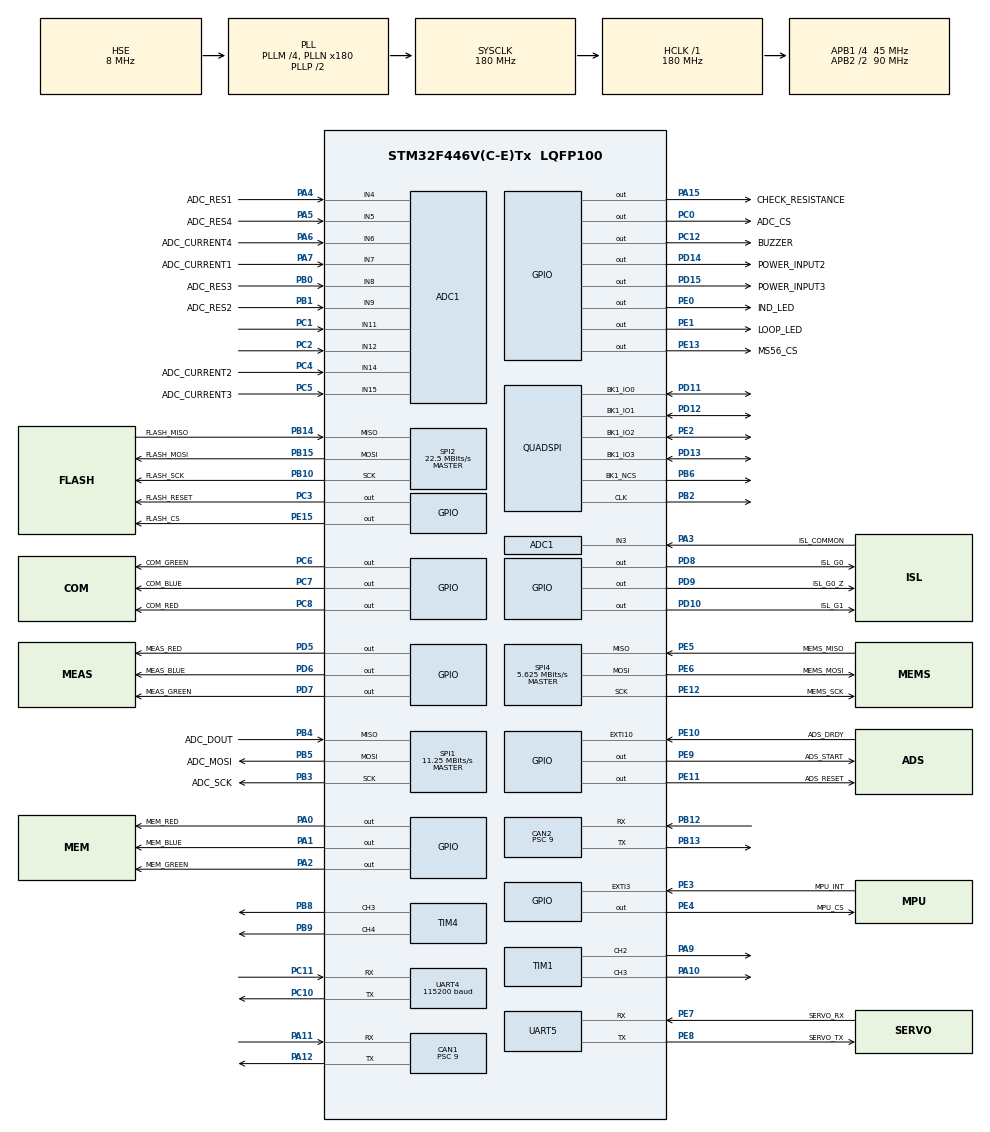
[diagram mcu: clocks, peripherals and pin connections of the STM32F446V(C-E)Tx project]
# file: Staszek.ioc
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NVIC.CAN1_RX1_IRQn=true\:5\:0\:true\:false\:true\:true\:true
PH0-OSC_IN.Signal=RCC_OSC_IN
SPI4.VirtualType=VM_MASTER
QUADSPI.ClockPrescaler=3
SPI1.VirtualType=VM_MASTER
SPI2.VirtualType=VM_MASTER
PB10.Mode=Full_Duplex_Master
Dma.SPI4_TX.1.PeriphDataAlignment=DMA_PDATAALIGN_BYTE
PC12.Signal=GPIO_Output
PB14.GPIO_Label=FLASH_MISO
PC6.GPIO_Label=COM_GREEN
PA6.GPIO_Label=ADC_CURRENT4
PB13.Signal=CAN2_TX
PD6.GPIO_Label=MEAS_BLUE
PE6.GPIO_Label=MEMS_MOSI
RCC.SYSCLKSource=RCC_SYSCLKSOURCE_PLLCLK
VP_TIM1_VS_no_output1.Mode=PWM Generation1 No Output
PA9.GPIO_ModeDefaultPP=GPIO_MODE_AF_OD
NVIC.SPI4_IRQn=true\:5\:0\:true\:false\:true\:true\:true
NVIC.CAN1_TX_IRQn=true\:5\:0\:true\:false\:true\:true\:true
Dma.SPI2_RX.2.Direction=DMA_PERIPH_TO_MEMORY
SPI1.Direction=SPI_DIRECTION_2LINES
Dma.SPI1_RX.5.Instance=DMA2_Stream0
PE2.Mode=Single Bank 1
RCC.APB2TimFreq_Value=180000000
PB6.Signal=QUADSPI_BK1_NCS
PC7.Signal=GPIO_Output
PB6.Mode=Single Bank 1
SPI1.CalculateBaudRate=11.25 MBits/s
PC3.Signal=GPIO_Output
PD8.Signal=GPIO_Output
PE5.Signal=SPI4_MISO
PA10.GPIO_ModeDefaultPP=GPIO_MODE_AF_OD
PE1.Signal=GPIO_Output
Dma.SPI4_RX.0.Priority=DMA_PRIORITY_LOW
QUADSPI.FlashSize=31
NVIC.EXTI15_10_IRQn=true\:5\:0\:true\:false\:true\:true\:true
Dma.SPI2_RX.2.MemDataAlignment=DMA_MDATAALIGN_BYTE
TIM4.Channel-PWM\ Generation3\ CH3=TIM_CHANNEL_3
NVIC.TIM8_TRG_COM_TIM14_IRQn=true\:0\:0\:true\:false\:true\:false\:true
PB2.Signal=QUADSPI_CLK
PB3.Mode=Full_Duplex_Master
SH.ADCx_IN15.0=ADC1_IN15,IN15
Dma.SPI2_RX.2.PeriphInc=DMA_PINC_DISABLE
PC4.GPIO_Label=ADC_CURRENT2
PE9.Signal=GPIO_Output
PB14.Mode=Full_Duplex_Master
PB1.GPIO_Label=ADC_RES2
PE4.GPIO_Label=MPU_CS
SH.ADCx_IN8.0=ADC1_IN8,IN8
SPI2.CalculateBaudRate=22.5 MBits/s
PE2.Signal=QUADSPI_BK1_IO2
Dma.SPI2_RX.2.PeriphDataAlignment=DMA_PDATAALIGN_BYTE
Dma.SPI1_RX.5.Priority=DMA_PRIORITY_LOW
Dma.SPI1_RX.5.FIFOMode=DMA_FIFOMODE_DISABLE
PE10.Signal=GPXTI10
Dma.SPI4_RX.0.Mode=DMA_NORMAL
VP_TIM1_VS_ClockSourceINT.Mode=Internal
ADC1.SamplingTime-0\#ChannelRegularConversion=ADC_SAMPLETIME_3CYCLES
CAN1.Prescaler=9
Mcu.Package=LQFP100
PB9.Signal=S_TIM4_CH4
PB1.Signal=ADCx_IN9
NVIC.TimeBase=TIM8_UP_TIM13_IRQn
SPI2.Mode=SPI_MODE_MASTER
SH.ADCx_IN14.0=ADC1_IN14,IN14
PD12.Signal=QUADSPI_BK1_IO1
Dma.SPI2_RX.2.MemInc=DMA_MINC_ENABLE
NVIC.TimeBaseIP=TIM13
PA10.Signal=S_TIM1_CH3
PE12.GPIO_Label=MEMS_SCK
PC11.Mode=Asynchronous
SH.ADCx_IN9.0=ADC1_IN9,IN9
RCC.APB2CLKDivider=RCC_HCLK_DIV2
RCC.APB1TimFreq_Value=90000000
PB13.Mode=Slave
VP_TIM14_VS_ClockSourceINT.Mode=Enable_Timer
TIM4.Channel-PWM\ Generation4\ CH4=TIM_CHANNEL_4
PE10.GPIO_Label=ADS_DRDY
PA4.GPIO_Label=ADC_RES1
PD15.Signal=GPIO_Output
CAN1.CalculateTimeQuantum=200.0
NVIC.UART4_IRQn=true\:5\:0\:true\:false\:true\:true\:true
PE12.Mode=Full_Duplex_Master
Dma.SPI2_TX.3.MemInc=DMA_MINC_ENABLE
NVIC.QUADSPI_IRQn=true\:5\:0\:true\:false\:true\:true\:true
NVIC.CAN2_TX_IRQn=true\:5\:0\:true\:false\:true\:true\:true
ADC1.Rank-0\#ChannelRegularConversion=1
PD9.GPIO_Label=ISL_G0_Z
SH.ADCx_IN6.0=ADC1_IN6,IN6
Dma.QUADSPI.6.Instance=DMA2_Stream7
Dma.SPI1_RX.5.MemDataAlignment=DMA_MDATAALIGN_BYTE
PC6.Signal=GPIO_Output
PC2.Signal=ADCx_IN12
PD7.Signal=GPIO_Output
NVIC.DMA2_Stream1_IRQn=true\:5\:0\:true\:false\:true\:false\:true
UART5.VirtualMode=Asynchronous
PC0.Signal=GPIO_Output
RCC.APB1CLKDivider=RCC_HCLK_DIV4
UART4.VirtualMode=Asynchronous
NVIC.CAN2_RX1_IRQn=true\:5\:0\:true\:false\:true\:true\:true
PA0-WKUP.GPIO_Label=MEM_RED
PA0-WKUP.Signal=GPIO_Output
Dma.SPI4_TX.1.PeriphInc=DMA_PINC_DISABLE
Dma.SPI2_TX.3.PeriphDataAlignment=DMA_PDATAALIGN_BYTE
PE8.Mode=Asynchronous
PD10.Signal=GPIO_Output
Dma.SPI2_RX.2.FIFOMode=DMA_FIFOMODE_DISABLE
SH.ADCx_IN7.0=ADC1_IN7,IN7
Dma.QUADSPI.6.MemDataAlignment=DMA_MDATAALIGN_BYTE
PE8.GPIO_Label=SERVO_TX
Dma.QUADSPI.6.PeriphDataAlignment=DMA_PDATAALIGN_BYTE
PA9.Signal=S_TIM1_CH2
TIM1.Channel-PWM\ Generation2\ CH2=TIM_CHANNEL_2
VP_TIM8_VS_ClockSourceINT.Mode=Internal
Dma.SPI2_TX.3.Mode=DMA_NORMAL
PE9.GPIO_Label=ADS_START
PB10.Signal=SPI2_SCK
PB14.Signal=SPI2_MISO
PA5.Signal=ADCx_IN5
PB9.GPIO_ModeDefaultPP=GPIO_MODE_AF_OD
PE1.GPIO_Label=LOOP_LED
NVIC.SPI1_IRQn=true\:5\:0\:true\:false\:true\:true\:true
Dma.SPI2_TX.3.Instance=DMA1_Stream4
PE6.Mode=Full_Duplex_Master
PE15.Signal=GPIO_Output
PB4.GPIO_Label=ADC_DOUT
PB15.GPIO_Label=FLASH_MOSI
PE8.Signal=UART5_TX
SPI1.Mode=SPI_MODE_MASTER
PA1.GPIO_Label=MEM_BLUE
Dma.QUADSPI.6.Mode=DMA_NORMAL
SH.ADCx_IN4.0=ADC1_IN4,IN4
PA13.Mode=Serial_Wire
TIM8.Period=49
PC7.GPIO_Label=COM_BLUE
Dma.SPI1_TX.4.PeriphInc=DMA_PINC_DISABLE
Dma.SPI1_TX.4.Priority=DMA_PRIORITY_LOW
PA4.Signal=ADCx_IN4
PB5.Signal=SPI1_MOSI
ADC1.master=1
PE13.GPIO_Label=MS56_CS
PD12.Mode=Single Bank 1
PA5.GPIO_Label=ADC_RES4
PD11.Signal=QUADSPI_BK1_IO0
PE5.GPIO_Label=MEMS_MISO
PC12.GPIO_Label=BUZZER
PA11.Signal=CAN1_RX
ProjectManager.HeapSize=0x200
NVIC.CAN2_SCE_IRQn=true\:5\:0\:true\:false\:true\:true\:true
NVIC.TIM8_UP_TIM13_IRQn=true\:0\:0\:true\:false\:true\:true\:true
SH.ADCx_IN5.0=ADC1_IN5,IN5
VP_TIM4_VS_ClockSourceINT.Mode=Internal
Dma.SPI4_TX.1.Priority=DMA_PRIORITY_LOW
NVIC.PriorityGroup=NVIC_PRIORITYGROUP_4
PE3.Signal=GPXTI3
Dma.SPI2_TX.3.PeriphInc=DMA_PINC_DISABLE
PC3.GPIO_Label=FLASH_RESET
Dma.SPI2_TX.3.FIFOMode=DMA_FIFOMODE_DISABLE
TIM1.Channel-PWM\ Generation3\ CH3=TIM_CHANNEL_3
PB0.Signal=ADCx_IN8
Dma.SPI4_RX.0.MemDataAlignment=DMA_MDATAALIGN_BYTE
PC1.Signal=ADCx_IN11
NVIC.CAN1_RX0_IRQn=true\:5\:0\:true\:false\:true\:true\:true
Mcu.Family=STM32F4
Dma.SPI1_TX.4.MemInc=DMA_MINC_ENABLE
RCC.CortexFreq_Value=180000000
NVIC.CAN2_RX0_IRQn=true\:5\:0\:true\:false\:true\:true\:true
Dma.SPI4_TX.1.MemDataAlignment=DMA_MDATAALIGN_BYTE
PE11.GPIO_Label=ADS_RESET
Dma.SPI1_RX.5.PeriphDataAlignment=DMA_PDATAALIGN_BYTE
PC10.Signal=UART4_TX
SPI4.Direction=SPI_DIRECTION_2LINES
NVIC.EXTI3_IRQn=true\:5\:0\:true\:false\:true\:true\:true
PC0.GPIO_Label=ADC_CS
PA11.Mode=Master
PB0.GPIO_Label=ADC_RES3
Dma.QUADSPI.6.PeriphInc=DMA_PINC_DISABLE
NVIC.DMA1_Stream4_IRQn=true\:5\:0\:true\:false\:true\:false\:true
PB15.Signal=SPI2_MOSI
ProjectManager.StackSize=0x400
PD13.Signal=QUADSPI_BK1_IO3
PA15.GPIO_Label=CHECK_RESISTANCE
Dma.SPI4_RX.0.MemInc=DMA_MINC_ENABLE
PA12.Signal=CAN1_TX
SPI4.Mode=SPI_MODE_MASTER
UART4.BaudRate=115200
RCC.HCLKFreq_Value=180000000
SH.ADCx_IN3.0=ADC1_IN3,IN3
Dma.SPI4_TX.1.Direction=DMA_MEMORY_TO_PERIPH
Dma.SPI2_TX.3.Priority=DMA_PRIORITY_LOW
NVIC.DMA2_Stream0_IRQn=true\:5\:0\:true\:false\:true\:false\:true
NVIC.CAN1_SCE_IRQn=true\:5\:0\:true\:false\:true\:true\:true
RCC.AHBFreq_Value=180000000
PH0-OSC_IN.Mode=HSE-External-Oscillator
ADC1.Channel-0\#ChannelRegularConversion=ADC_CHANNEL_3
Dma.SPI2_RX.2.Instance=DMA1_Stream3
RCC.HSE_VALUE=8000000
PB8.GPIO_ModeDefaultPP=GPIO_MODE_AF_OD
Dma.SPI1_TX.4.FIFOMode=DMA_FIFOMODE_DISABLE
PB4.Mode=Full_Duplex_Master
PE13.Signal=GPIO_Output
PA14.Mode=Serial_Wire
CAN2.Prescaler=9
Dma.QUADSPI.6.Direction=DMA_PERIPH_TO_MEMORY
PB5.Mode=Full_Duplex_Master
Dma.SPI4_TX.1.Instance=DMA2_Stream1
NVIC.SPI2_IRQn=true\:5\:0\:true\:false\:true\:true\:true
Dma.SPI1_TX.4.MemDataAlignment=DMA_MDATAALIGN_BYTE
PE4.Signal=GPIO_Output
SPI4.BaudRatePrescaler=SPI_BAUDRATEPRESCALER_16
PD7.GPIO_Label=MEAS_GREEN
PH1-OSC_OUT.Mode=HSE-External-Oscillator
PA6.Signal=ADCx_IN6
PB12.Mode=Slave
NVIC.DMA2_Stream7_IRQn=true\:5\:0\:true\:false\:true\:false\:true
CAN2.BS1=CAN_BS1_6TQ
CAN2.BS2=CAN_BS2_6TQ
Dma.QUADSPI.6.FIFOMode=DMA_FIFOMODE_DISABLE
Dma.SPI2_RX.2.Priority=DMA_PRIORITY_LOW
Dma.QUADSPI.6.Priority=DMA_PRIORITY_LOW
Dma.SPI1_TX.4.Direction=DMA_MEMORY_TO_PERIPH
PD5.GPIO_Label=MEAS_RED
PA2.GPIO_Label=MEM_GREEN
Dma.SPI1_RX.5.PeriphInc=DMA_PINC_DISABLE
PA15.Signal=GPIO_Output
PE0.GPIO_Label=IND_LED
TIM8.Prescaler=179
PB5.GPIO_Label=ADC_MOSI
Dma.Request2=SPI2_RX
Dma.Request1=SPI4_TX
Dma.SPI4_RX.0.PeriphInc=DMA_PINC_DISABLE
Dma.Request4=SPI1_TX
Dma.Request3=SPI2_TX
Dma.Request6=QUADSPI
Dma.Request5=SPI1_RX
SPI2.Direction=SPI_DIRECTION_2LINES
PC5.Signal=ADCx_IN15
PE7.Signal=UART5_RX
PD6.Signal=GPIO_Output
Dma.Request0=SPI4_RX
SPI1.BaudRatePrescaler=SPI_BAUDRATEPRESCALER_8
Dma.SPI2_TX.3.Direction=DMA_MEMORY_TO_PERIPH
PB4.Signal=SPI1_MISO
PA3.Signal=ADCx_IN3
PB3.GPIO_Label=ADC_SCK
Dma.SPI4_TX.1.MemInc=DMA_MINC_ENABLE
RCC.PLLSourceVirtual=RCC_PLLSOURCE_HSE
Dma.SPI4_TX.1.Mode=DMA_NORMAL
PD15.GPIO_Label=POWER_INPUT3
PC9.GPIO_Label=STASZEK_RECO_PWM
Dma.SPI2_TX.3.MemDataAlignment=DMA_MDATAALIGN_BYTE
SH.S_TIM4_CH4.0=TIM4_CH4,PWM Generation4 CH4
PC11.Signal=UART4_RX
Dma.SPI1_TX.4.PeriphDataAlignment=DMA_PDATAALIGN_BYTE
PC8.Signal=GPIO_Output
PC4.Signal=ADCx_IN14
PC10.Mode=Asynchronous
Dma.QUADSPI.6.MemInc=DMA_MINC_ENABLE
PD9.Signal=GPIO_Output
PD5.Signal=GPIO_Output
Dma.SPI1_TX.4.Instance=DMA2_Stream5
Dma.SPI2_RX.2.Mode=DMA_NORMAL
TIM1.Channel-PWM\ Generation1\ No\ Output=TIM_CHANNEL_1
PD8.GPIO_Label=ISL_G0
PC8.GPIO_Label=COM_RED
PA13.Signal=SYS_JTMS-SWDIO
SH.ADCx_IN12.0=ADC1_IN12,IN12
Dma.SPI4_TX.1.FIFOMode=DMA_FIFOMODE_DISABLE
PE15.GPIO_Label=FLASH_CS
CAN1.BS2=CAN_BS2_6TQ
CAN1.BS1=CAN_BS1_6TQ
ProjectManager.TargetToolchain=SW4STM32
PB10.GPIO_Label=FLASH_SCK
SH.S_TIM4_CH3.0=TIM4_CH3,PWM Generation3 CH3
PD13.Mode=Single Bank 1
Dma.SPI4_RX.0.PeriphDataAlignment=DMA_PDATAALIGN_BYTE
RCC.USBFreq_Value=180000000
PD10.GPIO_Label=ISL_G1
NVIC.DMA2_Stream3_IRQn=true\:5\:0\:true\:false\:true\:false\:true
PE11.Signal=GPIO_Output
PA1.Signal=GPIO_Output
SPI4.CRCCalculation=SPI_CRCCALCULATION_DISABLE
board=custom
RCC.VCOOutputFreq_Value=360000000
PB15.Mode=Full_Duplex_Master
RCC.APB2Freq_Value=90000000
SH.ADCx_IN11.0=ADC1_IN11,IN11
VP_SYS_VS_tim13.Mode=TIM13
SH.S_TIM1_CH2.0=TIM1_CH2,PWM Generation2 CH2
PE5.Mode=Full_Duplex_Master
NVIC.DMA2_Stream5_IRQn=true\:5\:0\:true\:false\:true\:false\:true
CAN2.CalculateTimeQuantum=200.0
PH1-OSC_OUT.Signal=RCC_OSC_OUT
SPI4.CalculateBaudRate=5.625 MBits/s
PD14.GPIO_Label=POWER_INPUT2
PE6.Signal=SPI4_MOSI
Mcu.Name=STM32F446V(C-E)Tx
PE0.Signal=GPIO_Output
PE7.GPIO_Label=SERVO_RX
PE12.Signal=SPI4_SCK
PA2.Signal=GPIO_Output
PD14.Signal=GPIO_Output
PB3.Signal=SPI1_SCK
RCC.SYSCLKFreq_VALUE=180000000
PE7.Mode=Asynchronous
PA7.GPIO_Label=ADC_CURRENT1
PA12.Mode=Master
PC5.GPIO_Label=ADC_CURRENT3
Dma.SPI4_RX.0.Direction=DMA_PERIPH_TO_MEMORY
Dma.SPI1_RX.5.MemInc=DMA_MINC_ENABLE
Dma.SPI4_RX.0.Instance=DMA2_Stream3
PB2.Mode=Single Bank 1
PA14.Signal=SYS_JTCK-SWCLK
Dma.SPI1_TX.4.Mode=DMA_NORMAL
PD11.Mode=Single Bank 1
SH.S_TIM1_CH3.0=TIM1_CH3,PWM Generation3 CH3
ADC1.NbrOfConversionFlag=1
RCC.PLLM=4
Dma.SPI1_RX.5.Mode=DMA_NORMAL
RCC.PLLN=180
PB8.Signal=S_TIM4_CH3
PE3.GPIO_Label=MPU_INT
Dma.SPI1_RX.5.Direction=DMA_PERIPH_TO_MEMORY
NVIC.DMA1_Stream3_IRQn=true\:5\:0\:true\:false\:true\:false\:true
PC9.Signal=S_TIM3_CH4
RCC.APB1Freq_Value=45000000
PB12.Signal=CAN2_RX
PA3.GPIO_Label=ISL_COMMON
SH.S_TIM3_CH4.0=TIM3_CH4
PA7.Signal=ADCx_IN7
Dma.SPI4_RX.0.FIFOMode=DMA_FIFOMODE_DISABLE

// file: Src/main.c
/* USER CODE BEGIN Header */
/**
  ******************************************************************************
  * @file           : main.c
  * @brief          : Main program body
  ******************************************************************************
  * @attention
  *
  * <h2><center>&copy; Copyright (c) 2020 STMicroelectronics.
  * All rights reserved.</center></h2>
  *
  * This software component is licensed by ST under BSD 3-Clause license,
  * the "License"; You may not use this file except in compliance with the
  * License. You may obtain a copy of the License at:
  *                        opensource.org/licenses/BSD-3-Clause
  *
  ******************************************************************************
  */
/* USER CODE END Header */

#include "main.h"
#include "adc.h"
#include "can.h"
#include "dma.h"
#include "quadspi.h"
#include "spi.h"
#include "tim.h"
#include "usart.h"
#include "gpio.h"

/* USER CODE BEGIN Includes */
#include "SS_common.h"
#include "SS_platform.h"

/* USER CODE END Includes */

void SystemClock_Config(void);

int main(void)
{

  /* MCU Configuration--------------------------------------------------------*/

  /* Reset of all peripherals, Initializes the Flash interface and the Systick. */
  HAL_Init();

  /* Configure the system clock */
  SystemClock_Config();

  /* Initialize all configured peripherals */
  MX_GPIO_Init();
  MX_DMA_Init();
  MX_UART4_Init();
  MX_UART5_Init();
  MX_SPI1_Init();
  MX_ADC1_Init();
  MX_SPI4_Init();
  MX_SPI2_Init();
  MX_QUADSPI_Init();
  MX_TIM14_Init();
  /* USER CODE BEGIN 2 */

    MX_CAN1_Init();
    MX_CAN2_Init();
    MX_TIM1_Init();
    MX_TIM4_Init();
    MX_TIM8_Init();
    HAL_GPIO_WritePin(MPU_CS_GPIO_Port, MPU_CS_Pin, GPIO_PIN_SET);

    SS_platform_init();

    SS_init();

  /* USER CODE END 2 */

  /* Infinite loop */
    while(1) {

    }
}

void SystemClock_Config(void)
{
  RCC_OscInitTypeDef RCC_OscInitStruct = {0};
  RCC_ClkInitTypeDef RCC_ClkInitStruct = {0};

  /** Configure the main internal regulator output voltage
  */
  __HAL_RCC_PWR_CLK_ENABLE();
  __HAL_PWR_VOLTAGESCALING_CONFIG(PWR_REGULATOR_VOLTAGE_SCALE1);
  /** Initializes the CPU, AHB and APB busses clocks
  */
  RCC_OscInitStruct.OscillatorType = RCC_OSCILLATORTYPE_HSE;
  RCC_OscInitStruct.HSEState = RCC_HSE_ON;
  RCC_OscInitStruct.PLL.PLLState = RCC_PLL_ON;
  RCC_OscInitStruct.PLL.PLLSource = RCC_PLLSOURCE_HSE;
  RCC_OscInitStruct.PLL.PLLM = 4;
  RCC_OscInitStruct.PLL.PLLN = 180;
  RCC_OscInitStruct.PLL.PLLP = RCC_PLLP_DIV2;
  RCC_OscInitStruct.PLL.PLLQ = 2;
  RCC_OscInitStruct.PLL.PLLR = 2;
  if (HAL_RCC_OscConfig(&RCC_OscInitStruct) != HAL_OK)
  {
    Error_Handler();
  }
  /** Activate the Over-Drive mode
  */
  if (HAL_PWREx_EnableOverDrive() != HAL_OK)
  {
    Error_Handler();
  }
  /** Initializes the CPU, AHB and APB busses clocks
  */
  RCC_ClkInitStruct.ClockType = RCC_CLOCKTYPE_HCLK|RCC_CLOCKTYPE_SYSCLK
                              |RCC_CLOCKTYPE_PCLK1|RCC_CLOCKTYPE_PCLK2;
  RCC_ClkInitStruct.SYSCLKSource = RCC_SYSCLKSOURCE_PLLCLK;
  RCC_ClkInitStruct.AHBCLKDivider = RCC_SYSCLK_DIV1;
  RCC_ClkInitStruct.APB1CLKDivider = RCC_HCLK_DIV4;
  RCC_ClkInitStruct.APB2CLKDivider = RCC_HCLK_DIV2;

  if (HAL_RCC_ClockConfig(&RCC_ClkInitStruct, FLASH_LATENCY_5) != HAL_OK)
  {
    Error_Handler();
  }
}

 /**
  * @brief  Period elapsed callback in non blocking mode
  * @note   This function is called  when TIM13 interrupt took place, inside
  * HAL_TIM_IRQHandler(). It makes a direct call to HAL_IncTick() to increment
  * a global variable "uwTick" used as application time base.
  * @param  htim : TIM handle
  * @retval None
  */
void HAL_TIM_PeriodElapsedCallback(TIM_HandleTypeDef *htim)
{
  if (htim->Instance == TIM13) {
    HAL_IncTick();
  }
}

void Error_Handler(void)
{
}

/************************ (C) COPYRIGHT STMicroelectronics *****END OF FILE****/
